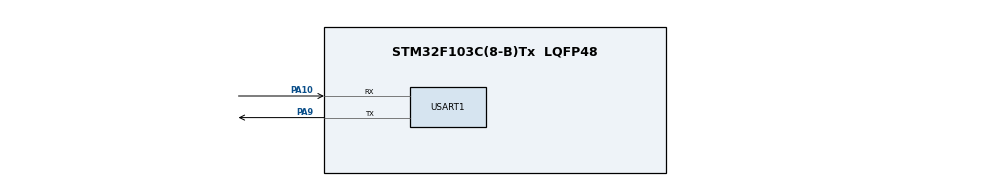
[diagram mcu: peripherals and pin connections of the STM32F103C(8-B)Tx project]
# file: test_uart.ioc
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FREERTOS.Tasks01=Task1,0,128,StartTask1,Default,NULL,Dynamic,NULL,NULL
Mcu.Family=STM32F1
Mcu.Name=STM32F103C(8-B)Tx
Mcu.Package=LQFP48
NVIC.PriorityGroup=NVIC_PRIORITYGROUP_4
NVIC.TIM4_IRQn=true\:15\:0\:false\:false\:true\:false\:false\:true\:true
NVIC.TimeBase=TIM4_IRQn
NVIC.TimeBaseIP=TIM4
PA10.Mode=Asynchronous
PA10.Signal=USART1_RX
PA13.Mode=Serial_Wire
PA13.Signal=SYS_JTMS-SWDIO
PA14.Mode=Serial_Wire
PA14.Signal=SYS_JTCK-SWCLK
PA9.Mode=Asynchronous
PA9.Signal=USART1_TX
PD0-OSC_IN.Mode=HSE-External-Oscillator
PD0-OSC_IN.Signal=RCC_OSC_IN
PD1-OSC_OUT.Mode=HSE-External-Oscillator
PD1-OSC_OUT.Signal=RCC_OSC_OUT
ProjectManager.HeapSize=0x200
ProjectManager.StackSize=0x400
ProjectManager.TargetToolchain=Makefile
RCC.APB1Freq_Value=8000000
RCC.APB2Freq_Value=8000000
RCC.SYSCLKSource=RCC_SYSCLKSOURCE_PLLCLK
USART1.VirtualMode=VM_ASYNC
VP_FREERTOS_VS_CMSIS_V1.Mode=CMSIS_V1
VP_SYS_VS_tim4.Mode=TIM4
board=custom

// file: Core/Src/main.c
/* USER CODE BEGIN Header */
/**
  ******************************************************************************
  * @file           : main.c
  * @brief          : Main program body
  ******************************************************************************
  * @attention
  *
  * Copyright (c) 2025 STMicroelectronics.
  * All rights reserved.
  *
  * This software is licensed under terms that can be found in the LICENSE file
  * in the root directory of this software component.
  * If no LICENSE file comes with this software, it is provided AS-IS.
  *
  ******************************************************************************
  */
/* USER CODE END Header */
#include "main.h"
#include "cmsis_os.h"
#include "usart.h"
#include "gpio.h"

/* USER CODE BEGIN Includes */
#include <stdarg.h>
#include <stdio.h>
#include <string.h>
/* USER CODE END Includes */

void SystemClock_Config(void);
void MX_FREERTOS_Init(void);

/* USER CODE BEGIN 0 */
  void mPrint(const char *format, ...) {
      char buffer[40];
      va_list args;
      va_start(args, format);
      vsnprintf(buffer, sizeof(buffer), format, args);
      va_end(args);
      HAL_UART_Transmit(&huart1, (uint8_t *)buffer, strlen(buffer), 1000);
  }
/* USER CODE END 0 */

int main(void)
{

  /* MCU Configuration--------------------------------------------------------*/

  /* Reset of all peripherals, Initializes the Flash interface and the Systick. */
  HAL_Init();

  /* Configure the system clock */
  SystemClock_Config();

  /* Initialize all configured peripherals */
  MX_GPIO_Init();
  MX_USART1_UART_Init();

  /* Call init function for freertos objects (in cmsis_os2.c) */
  MX_FREERTOS_Init();

  /* Start scheduler */
  osKernelStart();

  /* We should never get here as control is now taken by the scheduler */

  /* Infinite loop */
  while (1)
  {

    /* USER CODE BEGIN 3 */
     mPrint("Phan dat %d", 32);

  }
  /* USER CODE END 3 */
}

void SystemClock_Config(void)
{
  RCC_OscInitTypeDef RCC_OscInitStruct = {0};
  RCC_ClkInitTypeDef RCC_ClkInitStruct = {0};

  /** Initializes the RCC Oscillators according to the specified parameters
  * in the RCC_OscInitTypeDef structure.
  */
  RCC_OscInitStruct.OscillatorType = RCC_OSCILLATORTYPE_HSI;
  RCC_OscInitStruct.HSIState = RCC_HSI_ON;
  RCC_OscInitStruct.HSICalibrationValue = RCC_HSICALIBRATION_DEFAULT;
  RCC_OscInitStruct.PLL.PLLState = RCC_PLL_ON;
  RCC_OscInitStruct.PLL.PLLSource = RCC_PLLSOURCE_HSI_DIV2;
  RCC_OscInitStruct.PLL.PLLMUL = RCC_PLL_MUL2;
  if (HAL_RCC_OscConfig(&RCC_OscInitStruct) != HAL_OK)
  {
    Error_Handler();
  }

  /** Initializes the CPU, AHB and APB buses clocks
  */
  RCC_ClkInitStruct.ClockType = RCC_CLOCKTYPE_HCLK|RCC_CLOCKTYPE_SYSCLK
                              |RCC_CLOCKTYPE_PCLK1|RCC_CLOCKTYPE_PCLK2;
  RCC_ClkInitStruct.SYSCLKSource = RCC_SYSCLKSOURCE_PLLCLK;
  RCC_ClkInitStruct.AHBCLKDivider = RCC_SYSCLK_DIV1;
  RCC_ClkInitStruct.APB1CLKDivider = RCC_HCLK_DIV1;
  RCC_ClkInitStruct.APB2CLKDivider = RCC_HCLK_DIV1;

  if (HAL_RCC_ClockConfig(&RCC_ClkInitStruct, FLASH_LATENCY_0) != HAL_OK)
  {
    Error_Handler();
  }
}

void HAL_TIM_PeriodElapsedCallback(TIM_HandleTypeDef *htim)
{
  if (htim->Instance == TIM4)
  {
    HAL_IncTick();
  }
}

void Error_Handler(void)
{
  __disable_irq();
  while (1)
  {
  }
}

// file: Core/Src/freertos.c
/* USER CODE BEGIN Header */
/**
  ******************************************************************************
  * File Name          : freertos.c
  * Description        : Code for freertos applications
  ******************************************************************************
  * @attention
  *
  * Copyright (c) 2025 STMicroelectronics.
  * All rights reserved.
  *
  * This software is licensed under terms that can be found in the LICENSE file
  * in the root directory of this software component.
  * If no LICENSE file comes with this software, it is provided AS-IS.
  *
  ******************************************************************************
  */
/* USER CODE END Header */

#include "FreeRTOS.h"
#include "task.h"
#include "main.h"
#include "cmsis_os.h"

/* USER CODE BEGIN Variables */
osThreadId Task2Handle;
osThreadId Task3Handle;
/* USER CODE END Variables */
osThreadId Task1Handle;

/* USER CODE BEGIN FunctionPrototypes */
void StartTask2(void const * argument);
void StartTask3(void const * argument);
/* USER CODE END FunctionPrototypes */

void StartTask1(void const * argument);

void MX_FREERTOS_Init(void); /* (MISRA C 2004 rule 8.1) */

/* GetIdleTaskMemory prototype (linked to static allocation support) */
void vApplicationGetIdleTaskMemory( StaticTask_t **ppxIdleTaskTCBBuffer, StackType_t **ppxIdleTaskStackBuffer, uint32_t *pulIdleTaskStackSize );

/* USER CODE BEGIN GET_IDLE_TASK_MEMORY */
static StaticTask_t xIdleTaskTCBBuffer;
static StackType_t xIdleStack[configMINIMAL_STACK_SIZE];

void vApplicationGetIdleTaskMemory( StaticTask_t **ppxIdleTaskTCBBuffer, StackType_t **ppxIdleTaskStackBuffer, uint32_t *pulIdleTaskStackSize )
{
  *ppxIdleTaskTCBBuffer = &xIdleTaskTCBBuffer;
  *ppxIdleTaskStackBuffer = &xIdleStack[0];
  *pulIdleTaskStackSize = configMINIMAL_STACK_SIZE;
  /* place for user code */
}
/* USER CODE END GET_IDLE_TASK_MEMORY */

void MX_FREERTOS_Init(void) {

  /* Create the thread(s) */
  /* definition and creation of Task1 */
  osThreadDef(Task1, StartTask1, osPriorityNormal, 0, 128);
  Task1Handle = osThreadCreate(osThread(Task1), NULL);

  /* USER CODE BEGIN RTOS_THREADS */
  osThreadDef(Task2, StartTask2, -1, 0, 128);
  Task2Handle = osThreadCreate(osThread(Task2), NULL);
  osThreadDef(Task3, StartTask3, -2, 0, 128);
  Task2Handle = osThreadCreate(osThread(Task3), NULL);
  /* add threads, ... */
  /* USER CODE END RTOS_THREADS */

}

void StartTask1(void const * argument)
{
  /* USER CODE BEGIN StartTask1 */
  /* Infinite loop */
  while(1)
  {
    mPrint("Task1");
    osDelay(1000);
  }
  /* USER CODE END StartTask1 */
}

/* USER CODE BEGIN Application */
void StartTask2(void const * argument)
{
  /* USER CODE BEGIN StartTask1 */
  /* Infinite loop */
  while(1)
  {
    mPrint("Task2");
    osDelay(1000);
  }
  /* USER CODE END StartTask1 */
}
void StartTask3(void const * argument)
{
  /* USER CODE BEGIN StartTask1 */
  /* Infinite loop */
  while(1)
  {
    mPrint("Task3 ");
    osDelay(1000);
  }
  /* USER CODE END StartTask1 */
}
/* USER CODE END Application */
